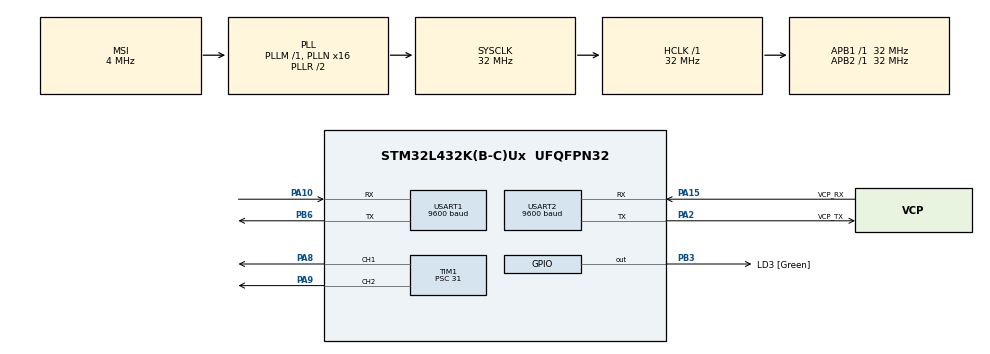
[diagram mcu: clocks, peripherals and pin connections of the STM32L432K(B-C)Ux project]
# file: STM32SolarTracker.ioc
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FREERTOS.Queues01=gpsRxQueue,32,uint8_t,0,Dynamic,NULL,NULL
FREERTOS.Tasks01=defaultTask,24,128,StartDefaultTask,Default,NULL,Dynamic,NULL,NULL;servoTask,24,128,StartServoTask,Default,NULL,Dynamic,NULL,NULL;gpsTask,32,128,StartGpsTask,Default,NULL,Dynamic,NULL,NULL;solarTask,16,256,StartSolarTask,Default,NULL,Dynamic,NULL,NULL
FREERTOS.configTOTAL_HEAP_SIZE=15360
Mcu.Family=STM32L4
Mcu.Name=STM32L432K(B-C)Ux
Mcu.Package=UFQFPN32
NVIC.PriorityGroup=NVIC_PRIORITYGROUP_4
NVIC.TIM6_DAC_IRQn=true\:15\:0\:false\:false\:true\:false\:false\:true\:true
NVIC.TimeBase=TIM6_DAC_IRQn
NVIC.TimeBaseIP=TIM6
NVIC.USART1_IRQn=true\:5\:0\:false\:false\:true\:true\:true\:true\:true
PA0.GPIO_Label=MCO [High speed clock in]
PA0.Mode=HSE-External-Clock-Source-for-LittleOrca
PA0.Signal=RCC_CK_IN
PA10.Mode=Asynchronous
PA10.Signal=USART1_RX
PA13\ (JTMS-SWDIO).GPIO_Label=SWDIO
PA13\ (JTMS-SWDIO).Mode=Serial_Wire
PA13\ (JTMS-SWDIO).Signal=SYS_JTMS-SWDIO
PA14\ (JTCK-SWCLK).GPIO_Label=SWCLK
PA14\ (JTCK-SWCLK).Mode=Serial_Wire
PA14\ (JTCK-SWCLK).Signal=SYS_JTCK-SWCLK
PA15\ (JTDI).GPIO_Label=VCP_RX
PA15\ (JTDI).Mode=Asynchronous
PA15\ (JTDI).Signal=USART2_RX
PA2.GPIO_Label=VCP_TX
PA2.Mode=Asynchronous
PA2.Signal=USART2_TX
PA8.Signal=S_TIM1_CH1
PA9.Signal=S_TIM1_CH2
PB3\ (JTDO-TRACESWO).GPIO_Label=LD3 [Green]
PB3\ (JTDO-TRACESWO).Signal=GPIO_Output
PB6.Mode=Asynchronous
PB6.Signal=USART1_TX
PC14-OSC32_IN\ (PC14).Mode=LSE-External-Oscillator
PC14-OSC32_IN\ (PC14).Signal=RCC_OSC32_IN
PC15-OSC32_OUT\ (PC15).Mode=LSE-External-Oscillator
PC15-OSC32_OUT\ (PC15).Signal=RCC_OSC32_OUT
ProjectManager.HeapSize=0x200
ProjectManager.StackSize=0x400
ProjectManager.TargetToolchain=Makefile
RCC.AHBFreq_Value=32000000
RCC.APB1Freq_Value=32000000
RCC.APB1TimFreq_Value=32000000
RCC.APB2Freq_Value=32000000
RCC.APB2TimFreq_Value=32000000
RCC.CortexFreq_Value=32000000
RCC.HCLKFreq_Value=32000000
RCC.HSE_VALUE=8000000
RCC.HSI16_VALUE=16000000
RCC.HSI48_VALUE=48000000
RCC.HSI_VALUE=16000000
RCC.MSI_VALUE=4000000
RCC.PLLMUL=RCC_PLLMUL_4
RCC.PLLN=16
RCC.SYSCLKFreq_VALUE=32000000
RCC.SYSCLKSource=RCC_SYSCLKSOURCE_PLLCLK
RCC.VCOOutputFreq_Value=64000000
SH.S_TIM1_CH1.0=TIM1_CH1,PWM Generation1 CH1
SH.S_TIM1_CH2.0=TIM1_CH2,PWM Generation2 CH2
TIM1.Channel-PWM\ Generation1\ CH1=TIM_CHANNEL_1
TIM1.Channel-PWM\ Generation2\ CH2=TIM_CHANNEL_2
TIM1.Period=19999
TIM1.Prescaler=31
TIM1.Pulse-PWM\ Generation1\ CH1=1500
TIM1.Pulse-PWM\ Generation2\ CH2=1500
USART1.BaudRate=9600
USART1.VirtualMode-Asynchronous=VM_ASYNC
USART2.BaudRate=9600
USART2.VirtualMode-Asynchronous=VM_ASYNC
VP_FREERTOS_VS_CMSIS_V2.Mode=CMSIS_V2
VP_SYS_VS_tim6.Mode=TIM6
VP_TIM1_VS_ClockSourceINT.Mode=Internal
board=NUCLEO-L432KC

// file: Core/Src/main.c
/* USER CODE BEGIN Header */
/**
  ******************************************************************************
  * @file           : main.c
  * @brief          : Main program body
  ******************************************************************************
  * @attention
  *
  * Copyright (c) 2026 STMicroelectronics.
  * All rights reserved.
  *
  * This software is licensed under terms that can be found in the LICENSE file
  * in the root directory of this software component.
  * If no LICENSE file comes with this software, it is provided AS-IS.
  *
  ******************************************************************************
  */
/* USER CODE END Header */
#include "main.h"
#include "cmsis_os.h"

/* USER CODE BEGIN Includes */
#include "gps_module.h"
extern uint8_t gps_rx_char;
/* USER CODE END Includes */

TIM_HandleTypeDef htim1;

UART_HandleTypeDef huart1;
UART_HandleTypeDef huart2;

/* Definitions for defaultTask */
osThreadId_t defaultTaskHandle;
const osThreadAttr_t defaultTask_attributes = {
  .name = "defaultTask",
  .stack_size = 128 * 4,
  .priority = (osPriority_t) osPriorityNormal,
};
/* Definitions for servoTask */
osThreadId_t servoTaskHandle;
const osThreadAttr_t servoTask_attributes = {
  .name = "servoTask",
  .stack_size = 128 * 4,
  .priority = (osPriority_t) osPriorityNormal,
};
/* Definitions for gpsTask */
osThreadId_t gpsTaskHandle;
const osThreadAttr_t gpsTask_attributes = {
  .name = "gpsTask",
  .stack_size = 128 * 4,
  .priority = (osPriority_t) osPriorityAboveNormal,
};
/* Definitions for solarTask */
osThreadId_t solarTaskHandle;
const osThreadAttr_t solarTask_attributes = {
  .name = "solarTask",
  .stack_size = 256 * 4,
  .priority = (osPriority_t) osPriorityBelowNormal,
};
/* Definitions for gpsRxQueue */
osMessageQueueId_t gpsRxQueueHandle;
const osMessageQueueAttr_t gpsRxQueue_attributes = {
  .name = "gpsRxQueue"
};
/* USER CODE BEGIN PV */
volatile uint32_t gps_rx_drop_count = 0;

/* USER CODE END PV */

void SystemClock_Config(void);
static void MX_GPIO_Init(void);
static void MX_USART2_UART_Init(void);
static void MX_TIM1_Init(void);
static void MX_USART1_UART_Init(void);
void StartDefaultTask(void *argument);
void StartServoTask(void *argument);
void StartGpsTask(void *argument);
void StartSolarTask(void *argument);

int main(void)
{

  /* MCU Configuration--------------------------------------------------------*/

  /* Reset of all peripherals, Initializes the Flash interface and the Systick. */
  HAL_Init();

  /* Configure the system clock */
  SystemClock_Config();

  /* Initialize all configured peripherals */
  MX_GPIO_Init();
  MX_USART2_UART_Init();
  MX_TIM1_Init();
  MX_USART1_UART_Init();
  /* USER CODE BEGIN 2 */

  /* Initialize GPS Module */
  GPS_Init();

  /* USER CODE END 2 */

  /* Init scheduler */
  osKernelInitialize();

  /* Create the queue(s) */
  /* creation of gpsRxQueue */
  gpsRxQueueHandle = osMessageQueueNew (256, sizeof(uint8_t), &gpsRxQueue_attributes);

  /* Create the thread(s) */
  /* creation of defaultTask */
  defaultTaskHandle = osThreadNew(StartDefaultTask, NULL, &defaultTask_attributes);

  /* creation of servoTask */
  servoTaskHandle = osThreadNew(StartServoTask, NULL, &servoTask_attributes);

  /* creation of gpsTask */
  gpsTaskHandle = osThreadNew(StartGpsTask, NULL, &gpsTask_attributes);

  /* creation of solarTask */
  solarTaskHandle = osThreadNew(StartSolarTask, NULL, &solarTask_attributes);

  /* Start scheduler */
  osKernelStart();

  /* We should never get here as control is now taken by the scheduler */

  /* Infinite loop */
  while (1)
  {

  }
}

void SystemClock_Config(void)
{
  RCC_OscInitTypeDef RCC_OscInitStruct = {0};
  RCC_ClkInitTypeDef RCC_ClkInitStruct = {0};

  /** Configure the main internal regulator output voltage
  */
  if (HAL_PWREx_ControlVoltageScaling(PWR_REGULATOR_VOLTAGE_SCALE1) != HAL_OK)
  {
    Error_Handler();
  }

  /** Configure LSE Drive Capability
  */
  HAL_PWR_EnableBkUpAccess();
  __HAL_RCC_LSEDRIVE_CONFIG(RCC_LSEDRIVE_LOW);

  /** Initializes the RCC Oscillators according to the specified parameters
  * in the RCC_OscInitTypeDef structure.
  */
  RCC_OscInitStruct.OscillatorType = RCC_OSCILLATORTYPE_LSE|RCC_OSCILLATORTYPE_MSI;
  RCC_OscInitStruct.LSEState = RCC_LSE_ON;
  RCC_OscInitStruct.MSIState = RCC_MSI_ON;
  RCC_OscInitStruct.MSICalibrationValue = 0;
  RCC_OscInitStruct.MSIClockRange = RCC_MSIRANGE_6;
  RCC_OscInitStruct.PLL.PLLState = RCC_PLL_ON;
  RCC_OscInitStruct.PLL.PLLSource = RCC_PLLSOURCE_MSI;
  RCC_OscInitStruct.PLL.PLLM = 1;
  RCC_OscInitStruct.PLL.PLLN = 16;
  RCC_OscInitStruct.PLL.PLLP = RCC_PLLP_DIV7;
  RCC_OscInitStruct.PLL.PLLQ = RCC_PLLQ_DIV2;
  RCC_OscInitStruct.PLL.PLLR = RCC_PLLR_DIV2;
  if (HAL_RCC_OscConfig(&RCC_OscInitStruct) != HAL_OK)
  {
    Error_Handler();
  }

  /** Initializes the CPU, AHB and APB buses clocks
  */
  RCC_ClkInitStruct.ClockType = RCC_CLOCKTYPE_HCLK|RCC_CLOCKTYPE_SYSCLK
                              |RCC_CLOCKTYPE_PCLK1|RCC_CLOCKTYPE_PCLK2;
  RCC_ClkInitStruct.SYSCLKSource = RCC_SYSCLKSOURCE_PLLCLK;
  RCC_ClkInitStruct.AHBCLKDivider = RCC_SYSCLK_DIV1;
  RCC_ClkInitStruct.APB1CLKDivider = RCC_HCLK_DIV1;
  RCC_ClkInitStruct.APB2CLKDivider = RCC_HCLK_DIV1;

  if (HAL_RCC_ClockConfig(&RCC_ClkInitStruct, FLASH_LATENCY_1) != HAL_OK)
  {
    Error_Handler();
  }

  /** Enable MSI Auto calibration
  */
  HAL_RCCEx_EnableMSIPLLMode();
}

static void MX_TIM1_Init(void)
{

  TIM_ClockConfigTypeDef sClockSourceConfig = {0};
  TIM_MasterConfigTypeDef sMasterConfig = {0};
  TIM_OC_InitTypeDef sConfigOC = {0};
  TIM_BreakDeadTimeConfigTypeDef sBreakDeadTimeConfig = {0};

  htim1.Instance = TIM1;
  htim1.Init.Prescaler = 31;
  htim1.Init.CounterMode = TIM_COUNTERMODE_UP;
  htim1.Init.Period = 19999;
  htim1.Init.ClockDivision = TIM_CLOCKDIVISION_DIV1;
  htim1.Init.RepetitionCounter = 0;
  htim1.Init.AutoReloadPreload = TIM_AUTORELOAD_PRELOAD_DISABLE;
  if (HAL_TIM_Base_Init(&htim1) != HAL_OK)
  {
    Error_Handler();
  }
  sClockSourceConfig.ClockSource = TIM_CLOCKSOURCE_INTERNAL;
  if (HAL_TIM_ConfigClockSource(&htim1, &sClockSourceConfig) != HAL_OK)
  {
    Error_Handler();
  }
  if (HAL_TIM_PWM_Init(&htim1) != HAL_OK)
  {
    Error_Handler();
  }
  sMasterConfig.MasterOutputTrigger = TIM_TRGO_RESET;
  sMasterConfig.MasterOutputTrigger2 = TIM_TRGO2_RESET;
  sMasterConfig.MasterSlaveMode = TIM_MASTERSLAVEMODE_DISABLE;
  if (HAL_TIMEx_MasterConfigSynchronization(&htim1, &sMasterConfig) != HAL_OK)
  {
    Error_Handler();
  }
  sConfigOC.OCMode = TIM_OCMODE_PWM1;
  sConfigOC.Pulse = 1500;
  sConfigOC.OCPolarity = TIM_OCPOLARITY_HIGH;
  sConfigOC.OCNPolarity = TIM_OCNPOLARITY_HIGH;
  sConfigOC.OCFastMode = TIM_OCFAST_DISABLE;
  sConfigOC.OCIdleState = TIM_OCIDLESTATE_RESET;
  sConfigOC.OCNIdleState = TIM_OCNIDLESTATE_RESET;
  if (HAL_TIM_PWM_ConfigChannel(&htim1, &sConfigOC, TIM_CHANNEL_1) != HAL_OK)
  {
    Error_Handler();
  }
  if (HAL_TIM_PWM_ConfigChannel(&htim1, &sConfigOC, TIM_CHANNEL_2) != HAL_OK)
  {
    Error_Handler();
  }
  sBreakDeadTimeConfig.OffStateRunMode = TIM_OSSR_DISABLE;
  sBreakDeadTimeConfig.OffStateIDLEMode = TIM_OSSI_DISABLE;
  sBreakDeadTimeConfig.LockLevel = TIM_LOCKLEVEL_OFF;
  sBreakDeadTimeConfig.DeadTime = 0;
  sBreakDeadTimeConfig.BreakState = TIM_BREAK_DISABLE;
  sBreakDeadTimeConfig.BreakPolarity = TIM_BREAKPOLARITY_HIGH;
  sBreakDeadTimeConfig.BreakFilter = 0;
  sBreakDeadTimeConfig.Break2State = TIM_BREAK2_DISABLE;
  sBreakDeadTimeConfig.Break2Polarity = TIM_BREAK2POLARITY_HIGH;
  sBreakDeadTimeConfig.Break2Filter = 0;
  sBreakDeadTimeConfig.AutomaticOutput = TIM_AUTOMATICOUTPUT_DISABLE;
  if (HAL_TIMEx_ConfigBreakDeadTime(&htim1, &sBreakDeadTimeConfig) != HAL_OK)
  {
    Error_Handler();
  }
  HAL_TIM_MspPostInit(&htim1);

}

static void MX_USART1_UART_Init(void)
{

  huart1.Instance = USART1;
  huart1.Init.BaudRate = 9600;
  huart1.Init.WordLength = UART_WORDLENGTH_8B;
  huart1.Init.StopBits = UART_STOPBITS_1;
  huart1.Init.Parity = UART_PARITY_NONE;
  huart1.Init.Mode = UART_MODE_TX_RX;
  huart1.Init.HwFlowCtl = UART_HWCONTROL_NONE;
  huart1.Init.OverSampling = UART_OVERSAMPLING_16;
  huart1.Init.OneBitSampling = UART_ONE_BIT_SAMPLE_DISABLE;
  huart1.AdvancedInit.AdvFeatureInit = UART_ADVFEATURE_NO_INIT;
  if (HAL_UART_Init(&huart1) != HAL_OK)
  {
    Error_Handler();
  }

}

static void MX_USART2_UART_Init(void)
{

  huart2.Instance = USART2;
  huart2.Init.BaudRate = 9600;
  huart2.Init.WordLength = UART_WORDLENGTH_8B;
  huart2.Init.StopBits = UART_STOPBITS_1;
  huart2.Init.Parity = UART_PARITY_NONE;
  huart2.Init.Mode = UART_MODE_TX_RX;
  huart2.Init.HwFlowCtl = UART_HWCONTROL_NONE;
  huart2.Init.OverSampling = UART_OVERSAMPLING_16;
  huart2.Init.OneBitSampling = UART_ONE_BIT_SAMPLE_DISABLE;
  huart2.AdvancedInit.AdvFeatureInit = UART_ADVFEATURE_NO_INIT;
  if (HAL_UART_Init(&huart2) != HAL_OK)
  {
    Error_Handler();
  }

}

static void MX_GPIO_Init(void)
{
  GPIO_InitTypeDef GPIO_InitStruct = {0};

  /* GPIO Ports Clock Enable */
  __HAL_RCC_GPIOC_CLK_ENABLE();
  __HAL_RCC_GPIOA_CLK_ENABLE();
  __HAL_RCC_GPIOB_CLK_ENABLE();

  /*Configure GPIO pin Output Level */
  HAL_GPIO_WritePin(LD3_GPIO_Port, LD3_Pin, GPIO_PIN_RESET);

  /*Configure GPIO pin : LD3_Pin */
  GPIO_InitStruct.Pin = LD3_Pin;
  GPIO_InitStruct.Mode = GPIO_MODE_OUTPUT_PP;
  GPIO_InitStruct.Pull = GPIO_NOPULL;
  GPIO_InitStruct.Speed = GPIO_SPEED_FREQ_LOW;
  HAL_GPIO_Init(LD3_GPIO_Port, &GPIO_InitStruct);

}

void StartDefaultTask(void *argument)
{
  for(;;)
  {
    osDelay(1);
  }
}

void StartServoTask(void *argument)
{
  for(;;)
  {
    osDelay(1);
  }
}

void StartGpsTask(void *argument)
{
  /* USER CODE BEGIN StartGpsTask */
  uint8_t rx_char = 0;
  for(;;)
  {
    if (gpsRxQueueHandle != NULL && osMessageQueueGet(gpsRxQueueHandle, &rx_char, NULL, 100) == osOK) {
      GPS_ProcessChar(rx_char);
      while (osMessageQueueGet(gpsRxQueueHandle, &rx_char, NULL, 0) == osOK) {
        GPS_ProcessChar(rx_char);
      }
    }

    GPS_Task();
  }
  /* USER CODE END StartGpsTask */
}

void StartSolarTask(void *argument)
{
  for(;;)
  {
    osDelay(1);
  }
}

void HAL_TIM_PeriodElapsedCallback(TIM_HandleTypeDef *htim)
{
  if (htim->Instance == TIM6)
  {
    HAL_IncTick();
  }
}

/**
  * @brief UART RX Complete Callback
  * Enqueue received GPS byte to RTOS message queue and re-arm RX interrupt.
  */
void HAL_UART_RxCpltCallback(UART_HandleTypeDef *huart)
{
  if (huart->Instance == USART1)
  {
    if (gpsRxQueueHandle != NULL) {
      if (osMessageQueuePut(gpsRxQueueHandle, &gps_rx_char, 0, 0) != osOK) {
        gps_rx_drop_count++;
      }
    } else {
      gps_rx_drop_count++;
    }

    /* Restart UART receive (non-blocking interrupt) */
    HAL_UART_Receive_IT(&huart1, &gps_rx_char, 1);
  }
}

void Error_Handler(void)
{
  __disable_irq();
  while (1)
  {
  }
}
